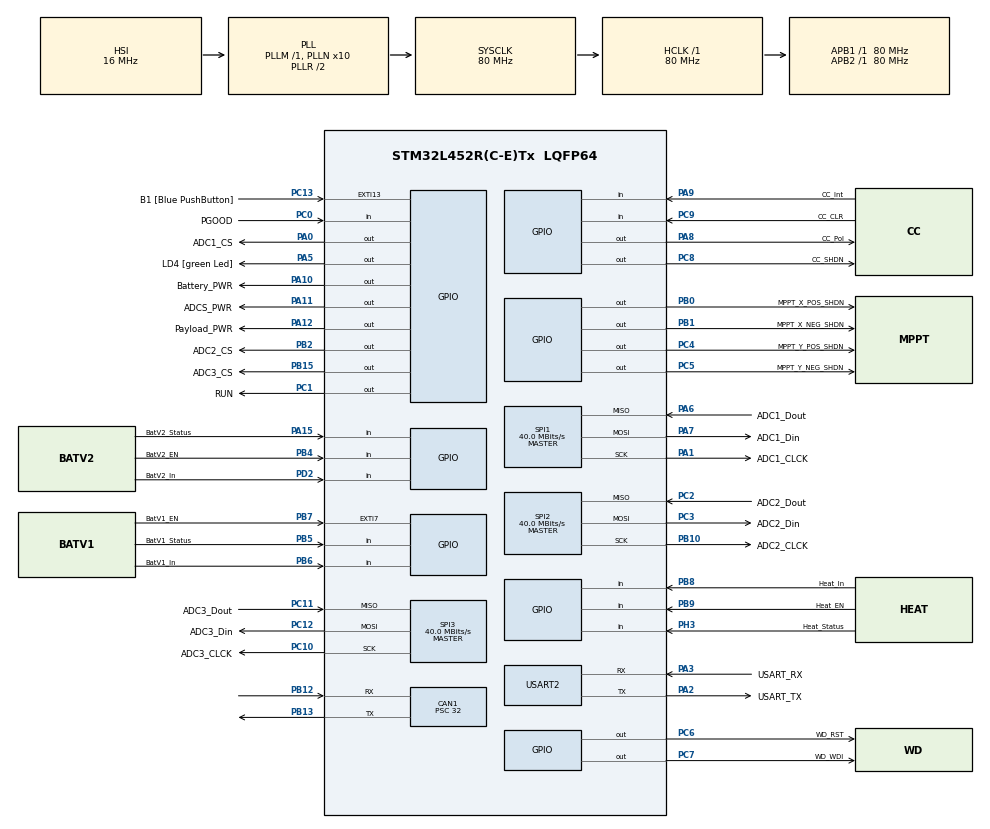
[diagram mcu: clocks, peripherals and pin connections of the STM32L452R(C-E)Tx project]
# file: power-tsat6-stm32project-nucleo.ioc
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CAN1.CalculateBaudRate=833333
CAN1.CalculateTimeBit=1200
CAN1.CalculateTimeQuantum=400.0
CAN1.Prescaler=32
Mcu.Family=STM32L4
Mcu.Name=STM32L452R(C-E)Tx
Mcu.Package=LQFP64
NVIC.PriorityGroup=NVIC_PRIORITYGROUP_4
PA0.GPIO_Label=ADC1_CS
PA0.Signal=GPIO_Output
PA1.GPIO_Label=ADC1_CLCK
PA1.Mode=Full_Duplex_Master
PA1.Signal=SPI1_SCK
PA10.GPIO_Label=Battery_PWR
PA10.Signal=GPIO_Output
PA11.GPIO_Label=ADCS_PWR
PA11.Signal=GPIO_Output
PA12.GPIO_Label=Payload_PWR
PA12.Signal=GPIO_Output
PA13\ (JTMS/SWDIO).GPIO_Label=TMS
PA13\ (JTMS/SWDIO).Mode=Serial_Wire
PA13\ (JTMS/SWDIO).Signal=SYS_JTMS-SWDIO
PA14\ (JTCK/SWCLK).GPIO_Label=TCK
PA14\ (JTCK/SWCLK).Mode=Serial_Wire
PA14\ (JTCK/SWCLK).Signal=SYS_JTCK-SWCLK
PA15\ (JTDI).GPIO_Label=BatV2_Status
PA15\ (JTDI).Signal=GPIO_Input
PA2.GPIO_Label=USART_TX
PA2.GPIO_Mode=GPIO_MODE_AF_PP
PA2.GPIO_PuPd=GPIO_NOPULL
PA2.GPIO_Speed=GPIO_SPEED_FREQ_VERY_HIGH
PA2.Mode=Asynchronous
PA2.Signal=USART2_TX
PA3.GPIO_Label=USART_RX
PA3.GPIO_Mode=GPIO_MODE_AF_PP
PA3.GPIO_PuPd=GPIO_NOPULL
PA3.GPIO_Speed=GPIO_SPEED_FREQ_VERY_HIGH
PA3.Mode=Asynchronous
PA3.Signal=USART2_RX
PA5.GPIO_Label=LD4 [green Led]
PA5.GPIO_ModeDefaultOutputPP=GPIO_MODE_OUTPUT_PP
PA5.GPIO_PuPd=GPIO_NOPULL
PA5.GPIO_Speed=GPIO_SPEED_FREQ_LOW
PA5.Signal=GPIO_Output
PA6.GPIO_Label=ADC1_Dout
PA6.Mode=Full_Duplex_Master
PA6.Signal=SPI1_MISO
PA7.GPIO_Label=ADC1_Din
PA7.Mode=Full_Duplex_Master
PA7.Signal=SPI1_MOSI
PA8.GPIO_Label=CC_Pol
PA8.Signal=GPIO_Output
PA9.GPIO_Label=CC_Int
PA9.GPIO_Mode=GPIO_MODE_INPUT
PA9.GPIO_PuPd=GPIO_NOPULL
PA9.Signal=GPIO_Input
PB0.GPIO_Label=MPPT_X_POS_SHDN
PB0.Signal=GPIO_Output
PB1.GPIO_Label=MPPT_X_NEG_SHDN
PB1.Signal=GPIO_Output
PB10.GPIO_Label=ADC2_CLCK
PB10.Mode=Full_Duplex_Master
PB10.Signal=SPI2_SCK
PB12.Mode=CAN_Activate
PB12.Signal=CAN1_RX
PB13.Mode=CAN_Activate
PB13.Signal=CAN1_TX
PB15.GPIO_Label=ADC3_CS
PB15.Signal=GPIO_Output
PB2.GPIO_Label=ADC2_CS
PB2.Signal=GPIO_Output
PB3\ (JTDO/TRACESWO).GPIO_Label=SWO
PB3\ (JTDO/TRACESWO).Signal=SYS_JTDO-SWO
PB4\ (NJTRST).GPIO_Label=BatV2_EN
PB4\ (NJTRST).Signal=GPIO_Input
PB5.GPIO_Label=BatV1_Status
PB5.Signal=GPIO_Input
PB6.GPIO_Label=BatV1_In
PB6.Signal=GPIO_Input
PB7.GPIO_Label=BatV1_EN
PB7.Signal=GPXTI7
PB8.GPIO_Label=Heat_In
PB8.Signal=GPIO_Input
PB9.GPIO_Label=Heat_EN
PB9.Signal=GPIO_Input
PC0.GPIO_Label=PGOOD
PC0.Signal=GPIO_Input
PC1.GPIO_Label=RUN
PC1.Signal=GPIO_Output
PC10.GPIO_Label=ADC3_CLCK
PC10.Mode=Full_Duplex_Master
PC10.Signal=SPI3_SCK
PC11.GPIO_Label=ADC3_Dout
PC11.Mode=Full_Duplex_Master
PC11.Signal=SPI3_MISO
PC12.GPIO_Label=ADC3_Din
PC12.Mode=Full_Duplex_Master
PC12.Signal=SPI3_MOSI
PC13.GPIO_Label=B1 [Blue PushButton]
PC13.GPIO_ModeDefaultEXTI=GPIO_MODE_IT_FALLING
PC13.GPIO_PuPd=GPIO_NOPULL
PC13.Signal=GPXTI13
PC14-OSC32_IN\ (PC14).Mode=LSE-External-Oscillator
PC14-OSC32_IN\ (PC14).Signal=RCC_OSC32_IN
PC15-OSC32_OUT\ (PC15).Mode=LSE-External-Oscillator
PC15-OSC32_OUT\ (PC15).Signal=RCC_OSC32_OUT
PC2.GPIO_Label=ADC2_Dout
PC2.Mode=Full_Duplex_Master
PC2.Signal=SPI2_MISO
PC3.GPIO_Label=ADC2_Din
PC3.Mode=Full_Duplex_Master
PC3.Signal=SPI2_MOSI
PC4.GPIO_Label=MPPT_Y_POS_SHDN
PC4.Signal=GPIO_Output
PC5.GPIO_Label=MPPT_Y_NEG_SHDN
PC5.Signal=GPIO_Output
PC6.GPIO_Label=WD_RST
PC6.Signal=GPIO_Output
PC7.GPIO_Label=WD_WDI
PC7.Signal=GPIO_Output
PC8.GPIO_Label=CC_SHDN
PC8.Signal=GPIO_Output
PC9.GPIO_Label=CC_CLR
PC9.Signal=GPIO_Input
PD2.GPIO_Label=BatV2_In
PD2.Signal=GPIO_Input
PH0-OSC_IN\ (PH0).Signal=RCC_OSC_IN
PH1-OSC_OUT\ (PH1).Signal=RCC_OSC_OUT
PH3-BOOT0\ (BOOT0).GPIO_Label=Heat_Status
PH3-BOOT0\ (BOOT0).Signal=GPIO_Input
ProjectManager.HeapSize=0x200
ProjectManager.StackSize=0x400
ProjectManager.TargetToolchain=STM32CubeIDE
RCC.ADCFreq_Value=64000000
RCC.AHBFreq_Value=80000000
RCC.APB1Freq_Value=80000000
RCC.APB1TimFreq_Value=80000000
RCC.APB2Freq_Value=80000000
RCC.APB2TimFreq_Value=80000000
RCC.CortexFreq_Value=80000000
RCC.HCLKFreq_Value=80000000
RCC.HSE_VALUE=8000000
RCC.HSI48_VALUE=48000000
RCC.HSI_VALUE=16000000
RCC.MSI_VALUE=4000000
RCC.PLLN=10
RCC.PLLSourceVirtual=RCC_PLLSOURCE_HSI
RCC.PREFETCH_ENABLE=1
RCC.SYSCLKFreq_VALUE=80000000
RCC.SYSCLKSource=RCC_SYSCLKSOURCE_PLLCLK
RCC.USBFreq_Value=64000000
RCC.VCOOutputFreq_Value=160000000
SPI1.CalculateBaudRate=40.0 MBits/s
SPI1.Direction=SPI_DIRECTION_2LINES
SPI1.Mode=SPI_MODE_MASTER
SPI1.VirtualType=VM_MASTER
SPI2.CalculateBaudRate=40.0 MBits/s
SPI2.Direction=SPI_DIRECTION_2LINES
SPI2.Mode=SPI_MODE_MASTER
SPI2.VirtualType=VM_MASTER
SPI3.CalculateBaudRate=40.0 MBits/s
SPI3.Direction=SPI_DIRECTION_2LINES
SPI3.Mode=SPI_MODE_MASTER
SPI3.VirtualType=VM_MASTER
USART2.VirtualMode-Asynchronous=VM_ASYNC
board=NUCLEO-L452RE

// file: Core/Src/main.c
/* USER CODE BEGIN Header */
/**
  ******************************************************************************
  * @file           : main.c
  * @brief          : Main program body
  ******************************************************************************
  * @attention
  *
  * Copyright (c) 2023 STMicroelectronics.
  * All rights reserved.
  *
  * This software is licensed under terms that can be found in the LICENSE file
  * in the root directory of this software component.
  * If no LICENSE file comes with this software, it is provided AS-IS.
  *
  ******************************************************************************
  */
/* USER CODE END Header */
#include "main.h"

/* USER CODE BEGIN Includes */
#include <stdio.h>
#include <stdlib.h>
#include "stm32l4xx_hal.h"
#include "ADC12_driver.h"
#include "LT365_driver.h"
#include "LTC11_driver.h"
#include "LTC29_driver.h"
#include "LTC41_driver.h"
#include "spi_config.h"
#include "TPS_driver.h"
#include "can.h"

/* USER CODE END Includes */

CAN_HandleTypeDef hcan1;

SPI_HandleTypeDef hspi1;
SPI_HandleTypeDef hspi2;
SPI_HandleTypeDef hspi3;

UART_HandleTypeDef huart2;

void SystemClock_Config(void);
static void MX_GPIO_Init(void);
static void MX_USART2_UART_Init(void);
static void MX_CAN1_Init(void);
static void MX_SPI1_Init(void);
static void MX_SPI2_Init(void);
static void MX_SPI3_Init(void);

int main(void)
{

  /* MCU Configuration--------------------------------------------------------*/

  /* Reset of all peripherals, Initializes the Flash interface and the Systick. */
  HAL_Init();

  /* Configure the system clock */
  SystemClock_Config();

  /* Initialize all configured peripherals */
  MX_GPIO_Init();
  MX_USART2_UART_Init();
  MX_CAN1_Init();
  MX_SPI1_Init();
  MX_SPI2_Init();
  MX_SPI3_Init();
  /* USER CODE BEGIN 2 */

  ADC1_Deselect();

  ADC2_Deselect();

  ADC3_Deselect();

  /* USER CODE END 2 */

  /* Infinite loop */
  /* USER CODE BEGIN WHILE */
  while (1)
  {

    // Send telemetry information to CDH every minute
    updateCDH();
    if(!CAN_Queue_IsEmpty(&can_queue))
      {
          CANMessage_t package;
          CAN_Queue_Dequeue(&can_queue, &package);
    if(package.command == 0xC0) {
			handleReset();

		} elif(package.command == 0xC1) {

			handlePLDOn();

		} elif(package.command == 0xC2) {
			handlePLDOff();

		} elif(package.command == 0xC3) {
			handleADCSOn();

		} elif(package.command == 0xC4) {

			handleADCSOff();

		} elif(package.command == 0xC5) {

			handleBatteryAccessOn();

		} elif(package.command == 0xC6) {

			handleBatteryAccessOff();

		} elif(package.command == 0xC7) {

			handleBatteryHeaterOn();

		}  elif(package.command == 0xC8) {

			handleBatteryHeaterOff();

		}  elif(package.command == 0xC9) {

			handleCheckDCDCCOnverterStatus();

		}

    // Delay for one minute
    HAL_Delay(60000); // Delay in milliseconds
  }
  /* USER CODE END 3 */
}

/**
 * @brief Collects and sends telemetry information to CDH
 * @retval None
 *
 */
void updateCDH(void)
{
  CANMessage_t package;
}

void SystemClock_Config(void)
{
  RCC_OscInitTypeDef RCC_OscInitStruct = {0};
  RCC_ClkInitTypeDef RCC_ClkInitStruct = {0};

  /** Configure the main internal regulator output voltage
  */
  if (HAL_PWREx_ControlVoltageScaling(PWR_REGULATOR_VOLTAGE_SCALE1) != HAL_OK)
  {
    Error_Handler();
  }

  /** Initializes the RCC Oscillators according to the specified parameters
  * in the RCC_OscInitTypeDef structure.
  */
  RCC_OscInitStruct.OscillatorType = RCC_OSCILLATORTYPE_HSI;
  RCC_OscInitStruct.HSIState = RCC_HSI_ON;
  RCC_OscInitStruct.HSICalibrationValue = RCC_HSICALIBRATION_DEFAULT;
  RCC_OscInitStruct.PLL.PLLState = RCC_PLL_ON;
  RCC_OscInitStruct.PLL.PLLSource = RCC_PLLSOURCE_HSI;
  RCC_OscInitStruct.PLL.PLLM = 1;
  RCC_OscInitStruct.PLL.PLLN = 10;
  RCC_OscInitStruct.PLL.PLLP = RCC_PLLP_DIV7;
  RCC_OscInitStruct.PLL.PLLQ = RCC_PLLQ_DIV2;
  RCC_OscInitStruct.PLL.PLLR = RCC_PLLR_DIV2;
  if (HAL_RCC_OscConfig(&RCC_OscInitStruct) != HAL_OK)
  {
    Error_Handler();
  }

  /** Initializes the CPU, AHB and APB buses clocks
  */
  RCC_ClkInitStruct.ClockType = RCC_CLOCKTYPE_HCLK|RCC_CLOCKTYPE_SYSCLK
                              |RCC_CLOCKTYPE_PCLK1|RCC_CLOCKTYPE_PCLK2;
  RCC_ClkInitStruct.SYSCLKSource = RCC_SYSCLKSOURCE_PLLCLK;
  RCC_ClkInitStruct.AHBCLKDivider = RCC_SYSCLK_DIV1;
  RCC_ClkInitStruct.APB1CLKDivider = RCC_HCLK_DIV1;
  RCC_ClkInitStruct.APB2CLKDivider = RCC_HCLK_DIV1;

  if (HAL_RCC_ClockConfig(&RCC_ClkInitStruct, FLASH_LATENCY_4) != HAL_OK)
  {
    Error_Handler();
  }
}

static void MX_CAN1_Init(void)
{

  hcan1.Instance = CAN1;
  hcan1.Init.Prescaler = 32;
  hcan1.Init.Mode = CAN_MODE_NORMAL;
  hcan1.Init.SyncJumpWidth = CAN_SJW_1TQ;
  hcan1.Init.TimeSeg1 = CAN_BS1_1TQ;
  hcan1.Init.TimeSeg2 = CAN_BS2_1TQ;
  hcan1.Init.TimeTriggeredMode = DISABLE;
  hcan1.Init.AutoBusOff = DISABLE;
  hcan1.Init.AutoWakeUp = DISABLE;
  hcan1.Init.AutoRetransmission = DISABLE;
  hcan1.Init.ReceiveFifoLocked = DISABLE;
  hcan1.Init.TransmitFifoPriority = DISABLE;
  if (HAL_CAN_Init(&hcan1) != HAL_OK)
  {
    Error_Handler();
  }

}

/**
  * @brief Wrapper for CAN message recieved, sends to function in can.c
  * @param None
  * @retval None
  */
void HAL_CAN_RxFifo0MsgPendingCallback(CAN_HandleTypeDef *hcan1)
{
  HAL_StatusTypeDef operation_status;
  operation_status = CAN_Message_Received();
  if(operation_status != HAL_OK)
  {
    //implement error handling
  }
}

static void MX_SPI1_Init(void)
{

  /* SPI1 parameter configuration*/
  hspi1.Instance = SPI1;
  hspi1.Init.Mode = SPI_MODE_MASTER;
  hspi1.Init.Direction = SPI_DIRECTION_2LINES;
  hspi1.Init.DataSize = SPI_DATASIZE_4BIT;
  hspi1.Init.CLKPolarity = SPI_POLARITY_LOW;
  hspi1.Init.CLKPhase = SPI_PHASE_1EDGE;
  hspi1.Init.NSS = SPI_NSS_SOFT;
  hspi1.Init.BaudRatePrescaler = SPI_BAUDRATEPRESCALER_2;
  hspi1.Init.FirstBit = SPI_FIRSTBIT_MSB;
  hspi1.Init.TIMode = SPI_TIMODE_DISABLE;
  hspi1.Init.CRCCalculation = SPI_CRCCALCULATION_DISABLE;
  hspi1.Init.CRCPolynomial = 7;
  hspi1.Init.CRCLength = SPI_CRC_LENGTH_DATASIZE;
  hspi1.Init.NSSPMode = SPI_NSS_PULSE_ENABLE;
  if (HAL_SPI_Init(&hspi1) != HAL_OK)
  {
    Error_Handler();
  }

}

static void MX_SPI2_Init(void)
{

  /* SPI2 parameter configuration*/
  hspi2.Instance = SPI2;
  hspi2.Init.Mode = SPI_MODE_MASTER;
  hspi2.Init.Direction = SPI_DIRECTION_2LINES;
  hspi2.Init.DataSize = SPI_DATASIZE_4BIT;
  hspi2.Init.CLKPolarity = SPI_POLARITY_LOW;
  hspi2.Init.CLKPhase = SPI_PHASE_1EDGE;
  hspi2.Init.NSS = SPI_NSS_SOFT;
  hspi2.Init.BaudRatePrescaler = SPI_BAUDRATEPRESCALER_2;
  hspi2.Init.FirstBit = SPI_FIRSTBIT_MSB;
  hspi2.Init.TIMode = SPI_TIMODE_DISABLE;
  hspi2.Init.CRCCalculation = SPI_CRCCALCULATION_DISABLE;
  hspi2.Init.CRCPolynomial = 7;
  hspi2.Init.CRCLength = SPI_CRC_LENGTH_DATASIZE;
  hspi2.Init.NSSPMode = SPI_NSS_PULSE_ENABLE;
  if (HAL_SPI_Init(&hspi2) != HAL_OK)
  {
    Error_Handler();
  }

}

static void MX_SPI3_Init(void)
{

  /* SPI3 parameter configuration*/
  hspi3.Instance = SPI3;
  hspi3.Init.Mode = SPI_MODE_MASTER;
  hspi3.Init.Direction = SPI_DIRECTION_2LINES;
  hspi3.Init.DataSize = SPI_DATASIZE_4BIT;
  hspi3.Init.CLKPolarity = SPI_POLARITY_LOW;
  hspi3.Init.CLKPhase = SPI_PHASE_1EDGE;
  hspi3.Init.NSS = SPI_NSS_SOFT;
  hspi3.Init.BaudRatePrescaler = SPI_BAUDRATEPRESCALER_2;
  hspi3.Init.FirstBit = SPI_FIRSTBIT_MSB;
  hspi3.Init.TIMode = SPI_TIMODE_DISABLE;
  hspi3.Init.CRCCalculation = SPI_CRCCALCULATION_DISABLE;
  hspi3.Init.CRCPolynomial = 7;
  hspi3.Init.CRCLength = SPI_CRC_LENGTH_DATASIZE;
  hspi3.Init.NSSPMode = SPI_NSS_PULSE_ENABLE;
  if (HAL_SPI_Init(&hspi3) != HAL_OK)
  {
    Error_Handler();
  }

}

static void MX_USART2_UART_Init(void)
{

  huart2.Instance = USART2;
  huart2.Init.BaudRate = 115200;
  huart2.Init.WordLength = UART_WORDLENGTH_8B;
  huart2.Init.StopBits = UART_STOPBITS_1;
  huart2.Init.Parity = UART_PARITY_NONE;
  huart2.Init.Mode = UART_MODE_TX_RX;
  huart2.Init.HwFlowCtl = UART_HWCONTROL_NONE;
  huart2.Init.OverSampling = UART_OVERSAMPLING_16;
  huart2.Init.OneBitSampling = UART_ONE_BIT_SAMPLE_DISABLE;
  huart2.AdvancedInit.AdvFeatureInit = UART_ADVFEATURE_NO_INIT;
  if (HAL_UART_Init(&huart2) != HAL_OK)
  {
    Error_Handler();
  }

}

static void MX_GPIO_Init(void)
{
  GPIO_InitTypeDef GPIO_InitStruct = {0};

  /* GPIO Ports Clock Enable */
  __HAL_RCC_GPIOC_CLK_ENABLE();
  __HAL_RCC_GPIOH_CLK_ENABLE();
  __HAL_RCC_GPIOA_CLK_ENABLE();
  __HAL_RCC_GPIOB_CLK_ENABLE();
  __HAL_RCC_GPIOD_CLK_ENABLE();

  /*Configure GPIO pin Output Level */
  HAL_GPIO_WritePin(GPIOC, RUN_Pin|MPPT_Y_POS_SHDN_Pin|MPPT_Y_NEG_SHDN_Pin|WD_RST_Pin
                          |WD_WDI_Pin|CC_SHDN_Pin, GPIO_PIN_RESET);

  /*Configure GPIO pin Output Level */
  HAL_GPIO_WritePin(GPIOA, ADC1_CS_Pin|LD4_Pin|CC_Pol_Pin|Battery_PWR_Pin
                          |ADCS_PWR_Pin|Payload_PWR_Pin, GPIO_PIN_RESET);

  /*Configure GPIO pin Output Level */
  HAL_GPIO_WritePin(GPIOB, MPPT_X_POS_SHDN_Pin|MPPT_X_NEG_SHDN_Pin|ADC2_CS_Pin|ADC3_CS_Pin, GPIO_PIN_RESET);

  /*Configure GPIO pin : B1_Pin */
  GPIO_InitStruct.Pin = B1_Pin;
  GPIO_InitStruct.Mode = GPIO_MODE_IT_FALLING;
  GPIO_InitStruct.Pull = GPIO_NOPULL;
  HAL_GPIO_Init(B1_GPIO_Port, &GPIO_InitStruct);

  /*Configure GPIO pins : PGOOD_Pin CC_CLR_Pin */
  GPIO_InitStruct.Pin = PGOOD_Pin|CC_CLR_Pin;
  GPIO_InitStruct.Mode = GPIO_MODE_INPUT;
  GPIO_InitStruct.Pull = GPIO_NOPULL;
  HAL_GPIO_Init(GPIOC, &GPIO_InitStruct);

  /*Configure GPIO pins : RUN_Pin MPPT_Y_POS_SHDN_Pin MPPT_Y_NEG_SHDN_Pin WD_RST_Pin
                           WD_WDI_Pin CC_SHDN_Pin */
  GPIO_InitStruct.Pin = RUN_Pin|MPPT_Y_POS_SHDN_Pin|MPPT_Y_NEG_SHDN_Pin|WD_RST_Pin
                          |WD_WDI_Pin|CC_SHDN_Pin;
  GPIO_InitStruct.Mode = GPIO_MODE_OUTPUT_PP;
  GPIO_InitStruct.Pull = GPIO_NOPULL;
  GPIO_InitStruct.Speed = GPIO_SPEED_FREQ_LOW;
  HAL_GPIO_Init(GPIOC, &GPIO_InitStruct);

  /*Configure GPIO pins : ADC1_CS_Pin LD4_Pin CC_Pol_Pin Battery_PWR_Pin
                           ADCS_PWR_Pin Payload_PWR_Pin */
  GPIO_InitStruct.Pin = ADC1_CS_Pin|LD4_Pin|CC_Pol_Pin|Battery_PWR_Pin
                          |ADCS_PWR_Pin|Payload_PWR_Pin;
  GPIO_InitStruct.Mode = GPIO_MODE_OUTPUT_PP;
  GPIO_InitStruct.Pull = GPIO_NOPULL;
  GPIO_InitStruct.Speed = GPIO_SPEED_FREQ_LOW;
  HAL_GPIO_Init(GPIOA, &GPIO_InitStruct);

  /*Configure GPIO pins : MPPT_X_POS_SHDN_Pin MPPT_X_NEG_SHDN_Pin ADC2_CS_Pin ADC3_CS_Pin */
  GPIO_InitStruct.Pin = MPPT_X_POS_SHDN_Pin|MPPT_X_NEG_SHDN_Pin|ADC2_CS_Pin|ADC3_CS_Pin;
  GPIO_InitStruct.Mode = GPIO_MODE_OUTPUT_PP;
  GPIO_InitStruct.Pull = GPIO_NOPULL;
  GPIO_InitStruct.Speed = GPIO_SPEED_FREQ_LOW;
  HAL_GPIO_Init(GPIOB, &GPIO_InitStruct);

  /*Configure GPIO pins : CC_Int_Pin BatV2_Status_Pin */
  GPIO_InitStruct.Pin = CC_Int_Pin|BatV2_Status_Pin;
  GPIO_InitStruct.Mode = GPIO_MODE_INPUT;
  GPIO_InitStruct.Pull = GPIO_NOPULL;
  HAL_GPIO_Init(GPIOA, &GPIO_InitStruct);

  /*Configure GPIO pin : BatV2_In_Pin */
  GPIO_InitStruct.Pin = BatV2_In_Pin;
  GPIO_InitStruct.Mode = GPIO_MODE_INPUT;
  GPIO_InitStruct.Pull = GPIO_NOPULL;
  HAL_GPIO_Init(BatV2_In_GPIO_Port, &GPIO_InitStruct);

  /*Configure GPIO pins : BatV2_EN_Pin BatV1_Status_Pin BatV1_In_Pin Heat_In_Pin
                           Heat_EN_Pin */
  GPIO_InitStruct.Pin = BatV2_EN_Pin|BatV1_Status_Pin|BatV1_In_Pin|Heat_In_Pin
                          |Heat_EN_Pin;
  GPIO_InitStruct.Mode = GPIO_MODE_INPUT;
  GPIO_InitStruct.Pull = GPIO_NOPULL;
  HAL_GPIO_Init(GPIOB, &GPIO_InitStruct);

  /*Configure GPIO pin : BatV1_EN_Pin */
  GPIO_InitStruct.Pin = BatV1_EN_Pin;
  GPIO_InitStruct.Mode = GPIO_MODE_IT_RISING;
  GPIO_InitStruct.Pull = GPIO_NOPULL;
  HAL_GPIO_Init(BatV1_EN_GPIO_Port, &GPIO_InitStruct);

  /*Configure GPIO pin : Heat_Status_Pin */
  GPIO_InitStruct.Pin = Heat_Status_Pin;
  GPIO_InitStruct.Mode = GPIO_MODE_INPUT;
  GPIO_InitStruct.Pull = GPIO_NOPULL;
  HAL_GPIO_Init(Heat_Status_GPIO_Port, &GPIO_InitStruct);

}

void Error_Handler(void)
{
  __disable_irq();
  while (1)
  {
  }
}
